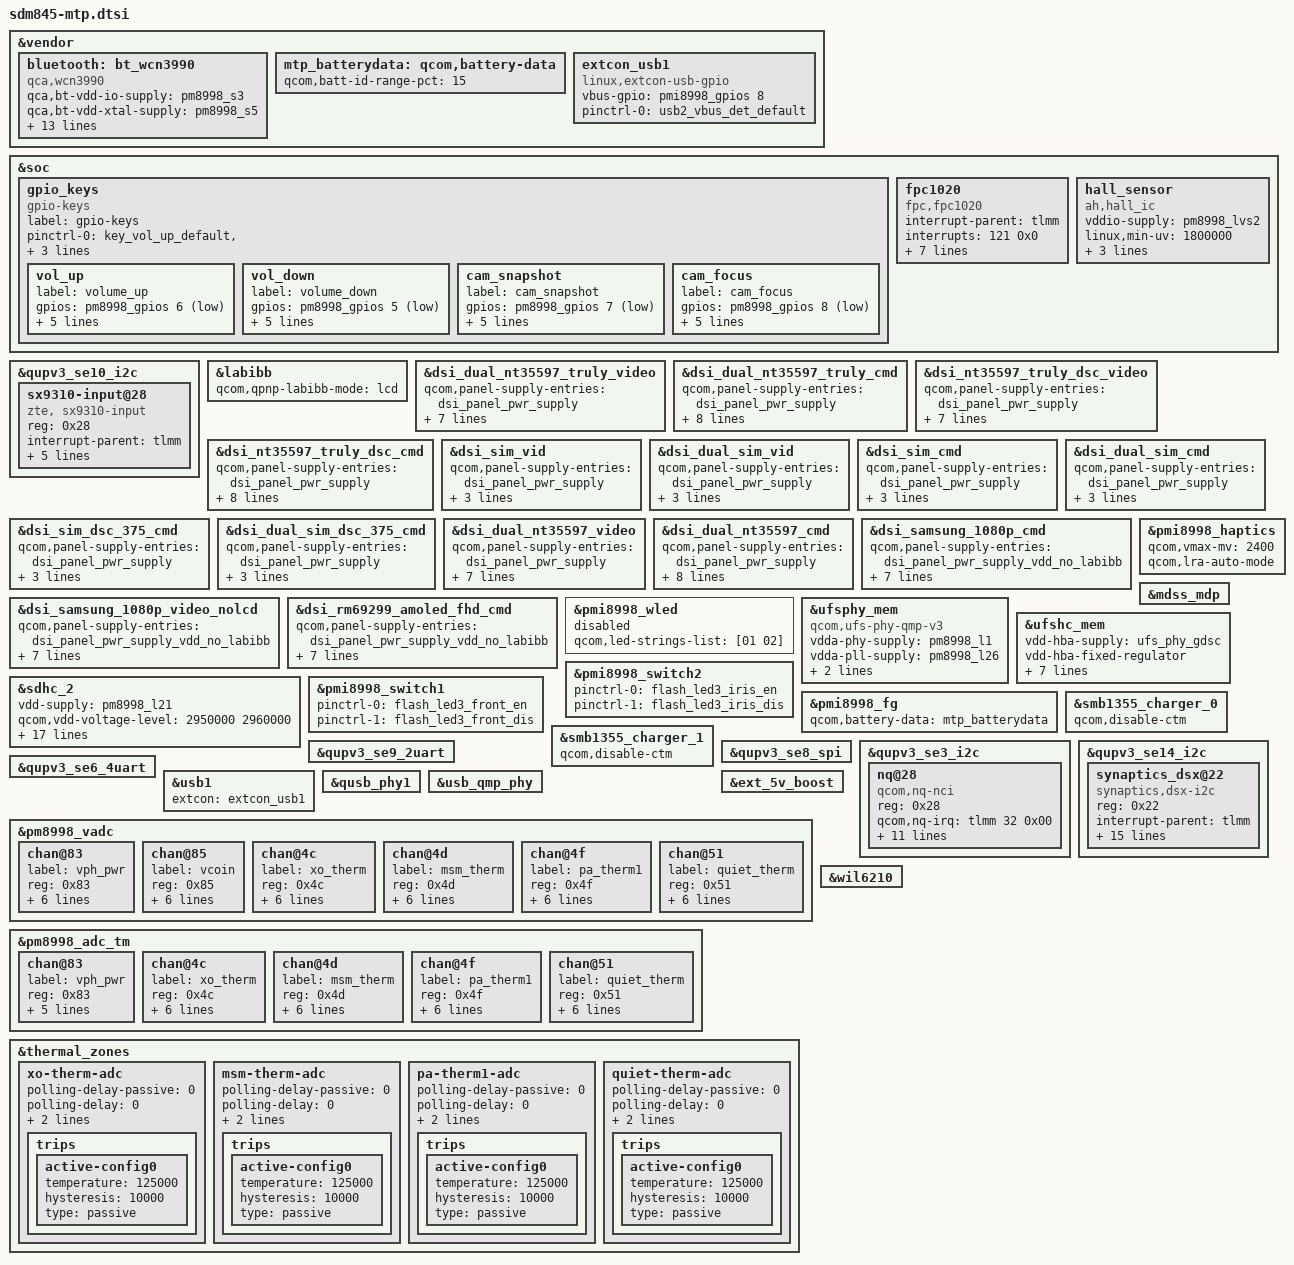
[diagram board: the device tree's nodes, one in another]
/* Copyright (c) 2016-2018, The Linux Foundation. All rights reserved.
 *
 * This program is free software; you can redistribute it and/or modify
 * it under the terms of the GNU General Public License version 2 and
 * only version 2 as published by the Free Software Foundation.
 *
 * This program is distributed in the hope that it will be useful,
 * but WITHOUT ANY WARRANTY; without even the implied warranty of
 * MERCHANTABILITY or FITNESS FOR A PARTICULAR PURPOSE.  See the
 * GNU General Public License for more details.
 */

#include <dt-bindings/gpio/gpio.h>
#include "sdm845-pmic-overlay.dtsi"
#include "sdm845-pinctrl-overlay.dtsi"
#include "zte-sdm845-camera-sensor-mtp.dtsi"
#include "smb1355.dtsi"

&vendor {
	bluetooth: bt_wcn3990 {
		compatible = "qca,wcn3990";
		qca,bt-vdd-io-supply = <&pm8998_s3>;
		qca,bt-vdd-xtal-supply = <&pm8998_s5>;
		qca,bt-vdd-core-supply = <&pm8998_l7>;
		qca,bt-vdd-pa-supply = <&pm8998_l17>;
		qca,bt-vdd-ldo-supply = <&pm8998_l25>;

		qca,bt-vdd-io-voltage-level = <1352000 1352000>;
		qca,bt-vdd-xtal-voltage-level = <2040000 2040000>;
		qca,bt-vdd-core-voltage-level = <1800000 1800000>;
		qca,bt-vdd-pa-voltage-level = <1304000 1304000>;
		qca,bt-vdd-ldo-voltage-level = <3312000 3312000>;

		qca,bt-vdd-io-current-level = <1>; /* LPM/PFM */
		qca,bt-vdd-xtal-current-level = <1>; /* LPM/PFM */
		qca,bt-vdd-core-current-level = <1>; /* LPM/PFM */
		qca,bt-vdd-pa-current-level = <1>; /* LPM/PFM */
		qca,bt-vdd-ldo-current-level = <1>; /* LPM/PFM */
	};
};

&soc {
	gpio_keys {
		compatible = "gpio-keys";
		label = "gpio-keys";

		pinctrl-names = "default";
		pinctrl-0 = <&key_vol_up_default
			     &key_vol_down_default
			     &key_cam_snapshot_default
			     &key_cam_focus_default>;

		vol_up {
			label = "volume_up";
			gpios = <&pm8998_gpios 6 GPIO_ACTIVE_LOW>;
			linux,input-type = <1>;
			linux,code = <115>;
			gpio-key,wakeup;
			debounce-interval = <15>;
			linux,can-disable;
		};

		/*add by yanshentao start*/
		vol_down {
			label = "volume_down";
			gpios = <&pm8998_gpios 5 GPIO_ACTIVE_LOW>;
			linux,input-type = <1>;
			linux,code = <114>;
			gpio-key,wakeup;
			debounce-interval = <15>;
			linux,can-disable;
		};
		/*add by yanshentao end*/

		cam_snapshot {
			label = "cam_snapshot";
			gpios = <&pm8998_gpios 7 GPIO_ACTIVE_LOW>;
			linux,input-type = <1>;
			linux,code = <766>;
			gpio-key,wakeup;
			debounce-interval = <15>;
			linux,can-disable;
		};

		cam_focus {
			label = "cam_focus";
			gpios = <&pm8998_gpios 8 GPIO_ACTIVE_LOW>;
			linux,input-type = <1>;
			linux,code = <528>;
			gpio-key,wakeup;
			debounce-interval = <15>;
			linux,can-disable;
		};
	};
	fpc1020 {
		status = "ok";
		compatible = "fpc,fpc1020";
		interrupt-parent = <&tlmm>;
		interrupts = <121 0x0>;
		fpc,gpio_rst	= <&tlmm 102 0x0>;
		fpc,gpio_irq	= <&tlmm 121 0x0>;
		fpc,gpio_pwr	= <&tlmm 87 0x0>;
		fpc,enable-on-boot;
		/* fpc,enable-wakeup; */

		pinctrl-names = "fpc1020_reset_reset",
		"fpc1020_reset_active",
		"fpc1020_irq_active";

		pinctrl-0 = <&msm_gpio_102>;
		pinctrl-1 = <&msm_gpio_102_output_high>;
		pinctrl-2 = <&msm_gpio_121>;
	};
	hall_sensor {
		compatible = "ah,hall_ic";
		vddio-supply = <&pm8998_lvs2>;
		linux,min-uv = <1800000>;
		linux,max-uv = <1800000>;
		ah,gpio_irq = <&tlmm 124 0x00>;
		linux,name = "hall_sensor";
	};
};

&qupv3_se10_i2c {
	status = "ok";
		sx9310-input@28 {
			compatible = "zte, sx9310-input";
			reg = <0x28>;
			//cc,irq_gpio = <&tlmm 17 0x0>;
			interrupt-parent = <&tlmm>;
			interrupts = <123 2>;
			interrupt-names = "sx9310_irq";
			pinctrl-names = "sx9310_active", "sx9310_sleep";
			pinctrl-0 = <&sx9500_int_active>;
			pinctrl-1 = <&sx9500_int_suspend >;
			vdd-supply = <&pm8998_l19>;
			svdd-supply = <&pm8998_s4>;
		};
};


&labibb {
	status = "ok";
	qcom,qpnp-labibb-mode = "lcd";
};

&dsi_dual_nt35597_truly_video {
	qcom,panel-supply-entries = <&dsi_panel_pwr_supply>;
	qcom,mdss-dsi-bl-pmic-control-type = "bl_ctrl_wled";
	qcom,mdss-dsi-bl-min-level = <1>;
	qcom,mdss-dsi-bl-max-level = <4095>;
	qcom,mdss-dsi-mode-sel-gpio-state = "dual_port";
	qcom,panel-mode-gpio = <&tlmm 52 0>;
	qcom,platform-reset-gpio = <&tlmm 6 0>;
};

&dsi_dual_nt35597_truly_cmd {
	qcom,panel-supply-entries = <&dsi_panel_pwr_supply>;
	qcom,mdss-dsi-bl-pmic-control-type = "bl_ctrl_wled";
	qcom,mdss-dsi-bl-min-level = <1>;
	qcom,mdss-dsi-bl-max-level = <4095>;
	qcom,mdss-dsi-mode-sel-gpio-state = "dual_port";
	qcom,panel-mode-gpio = <&tlmm 52 0>;
	qcom,platform-reset-gpio = <&tlmm 6 0>;
	qcom,platform-te-gpio = <&tlmm 10 0>;
};

&dsi_nt35597_truly_dsc_video {
	qcom,panel-supply-entries = <&dsi_panel_pwr_supply>;
	qcom,mdss-dsi-bl-pmic-control-type = "bl_ctrl_wled";
	qcom,mdss-dsi-bl-min-level = <1>;
	qcom,mdss-dsi-bl-max-level = <4095>;
	qcom,mdss-dsi-mode-sel-gpio-state = "single_port";
	qcom,panel-mode-gpio = <&tlmm 52 0>;
	qcom,platform-reset-gpio = <&tlmm 6 0>;
};

&dsi_nt35597_truly_dsc_cmd {
	qcom,panel-supply-entries = <&dsi_panel_pwr_supply>;
	qcom,mdss-dsi-bl-pmic-control-type = "bl_ctrl_wled";
	qcom,mdss-dsi-bl-min-level = <1>;
	qcom,mdss-dsi-bl-max-level = <4095>;
	qcom,mdss-dsi-mode-sel-gpio-state = "single_port";
	qcom,panel-mode-gpio = <&tlmm 52 0>;
	qcom,platform-reset-gpio = <&tlmm 6 0>;
	qcom,platform-te-gpio = <&tlmm 10 0>;
};

&dsi_sim_vid {
	qcom,panel-supply-entries = <&dsi_panel_pwr_supply>;
	qcom,mdss-dsi-bl-pmic-control-type = "bl_ctrl_wled";
	qcom,platform-reset-gpio = <&tlmm 6 0>;
};

&dsi_dual_sim_vid {
	qcom,panel-supply-entries = <&dsi_panel_pwr_supply>;
	qcom,mdss-dsi-bl-pmic-control-type = "bl_ctrl_wled";
	qcom,platform-reset-gpio = <&tlmm 6 0>;
};

&dsi_sim_cmd {
	qcom,panel-supply-entries = <&dsi_panel_pwr_supply>;
	qcom,mdss-dsi-bl-pmic-control-type = "bl_ctrl_wled";
	qcom,platform-reset-gpio = <&tlmm 6 0>;
};

&dsi_dual_sim_cmd {
	qcom,panel-supply-entries = <&dsi_panel_pwr_supply>;
	qcom,mdss-dsi-bl-pmic-control-type = "bl_ctrl_wled";
	qcom,platform-reset-gpio = <&tlmm 6 0>;
};

&dsi_sim_dsc_375_cmd {
	qcom,panel-supply-entries = <&dsi_panel_pwr_supply>;
	qcom,mdss-dsi-bl-pmic-control-type = "bl_ctrl_wled";
	qcom,platform-reset-gpio = <&tlmm 6 0>;
};

&dsi_dual_sim_dsc_375_cmd {
	qcom,panel-supply-entries = <&dsi_panel_pwr_supply>;
	qcom,mdss-dsi-bl-pmic-control-type = "bl_ctrl_wled";
	qcom,platform-reset-gpio = <&tlmm 6 0>;
};

&dsi_dual_nt35597_video {
	qcom,panel-supply-entries = <&dsi_panel_pwr_supply>;
	qcom,mdss-dsi-bl-pmic-control-type = "bl_ctrl_wled";
	qcom,mdss-dsi-bl-min-level = <1>;
	qcom,mdss-dsi-bl-max-level = <4095>;
	qcom,mdss-dsi-mode-sel-gpio-state = "dual_port";
	qcom,panel-mode-gpio = <&tlmm 52 0>;
	qcom,platform-reset-gpio = <&tlmm 6 0>;
};

&dsi_dual_nt35597_cmd {
	qcom,panel-supply-entries = <&dsi_panel_pwr_supply>;
	qcom,mdss-dsi-bl-pmic-control-type = "bl_ctrl_wled";
	qcom,mdss-dsi-bl-min-level = <1>;
	qcom,mdss-dsi-bl-max-level = <4095>;
	qcom,mdss-dsi-mode-sel-gpio-state = "dual_port";
	qcom,panel-mode-gpio = <&tlmm 52 0>;
	qcom,platform-reset-gpio = <&tlmm 6 0>;
	qcom,platform-te-gpio = <&tlmm 10 0>;
};

&dsi_samsung_1080p_cmd {
	qcom,panel-supply-entries = <&dsi_panel_pwr_supply_vdd_no_labibb>;
	qcom,mdss-dsi-mode-sel-gpio-state = "single_port";
	qcom,5v-boost-gpio = <&tlmm 40 0>;
	qcom,platform-reset-gpio = <&tlmm 6 0>;
	qcom,platform-te-gpio = <&tlmm 10 0>;
	qcom,dsp-reset-gpio = <&tlmm 23 0>;
	qcom,dsp-dsp_1v1 = <&tlmm 26 0>;
	qcom,dsp-wakeup-gpio = <&tlmm 24 0>;
};

&dsi_samsung_1080p_video_nolcd {
	qcom,panel-supply-entries = <&dsi_panel_pwr_supply_vdd_no_labibb>;
	qcom,mdss-dsi-mode-sel-gpio-state = "single_port";
	qcom,5v-boost-gpio = <&tlmm 40 0>;
	qcom,platform-reset-gpio = <&tlmm 6 0>;
	qcom,platform-te-gpio = <&tlmm 10 0>;
	qcom,dsp-reset-gpio = <&tlmm 23 0>;
	qcom,dsp-dsp_1v1 = <&tlmm 26 0>;
	qcom,dsp-wakeup-gpio = <&tlmm 24 0>;
};

&dsi_rm69299_amoled_fhd_cmd {
	qcom,panel-supply-entries = <&dsi_panel_pwr_supply_vdd_no_labibb>;
	qcom,mdss-dsi-mode-sel-gpio-state = "single_port";
	qcom,5v-boost-gpio = <&tlmm 40 0>;
	qcom,platform-reset-gpio = <&tlmm 6 0>;
	qcom,platform-te-gpio = <&tlmm 10 0>;
	qcom,dsp-reset-gpio = <&tlmm 23 0>;
	qcom,dsp-dsp_1v1 = <&tlmm 26 0>;
	qcom,dsp-wakeup-gpio = <&tlmm 24 0>;
};

&pmi8998_wled {
	status = "disabled";
	qcom,led-strings-list = [01 02];
};

&pmi8998_haptics {
	qcom,vmax-mv = <2400>;
	qcom,lra-auto-mode;
	status = "okay";
};

&mdss_mdp {
	#cooling-cells = <2>;
};

&ufsphy_mem {
	compatible = "qcom,ufs-phy-qmp-v3";

	vdda-phy-supply = <&pm8998_l1>; /* 0.88v */
	vdda-pll-supply = <&pm8998_l26>; /* 1.2v */
	vdda-phy-max-microamp = <62900>;
	vdda-pll-max-microamp = <18300>;

	status = "ok";
};

&ufshc_mem {
	vdd-hba-supply = <&ufs_phy_gdsc>;
	vdd-hba-fixed-regulator;
	vcc-supply = <&pm8998_l20>;
	vcc-voltage-level = <2950000 2960000>;
	vccq2-supply = <&pm8998_s4>;
	vcc-max-microamp = <600000>;
	vccq2-max-microamp = <600000>;

	qcom,vddp-ref-clk-supply = <&pm8998_l2>;
	qcom,vddp-ref-clk-max-microamp = <100>;

	status = "ok";
};

&sdhc_2 {
	vdd-supply = <&pm8998_l21>;
	qcom,vdd-voltage-level = <2950000 2960000>;
	qcom,vdd-current-level = <200 800000>;

	vdd-io-supply = <&pm8998_l13>;
	qcom,vdd-io-voltage-level = <1808000 2960000>;
	qcom,vdd-io-current-level = <200 22000>;

	pinctrl-names = "active", "sleep", "ds_400KHz",
			"ds_50MHz", "ds_100MHz", "ds_200MHz";
	pinctrl-0 = <&sdc2_clk_on  &sdc2_cmd_on &sdc2_data_on &storage_cd>;
	pinctrl-1 = <&sdc2_clk_off &sdc2_cmd_off &sdc2_data_off &storage_cd>;
	pinctrl-2 = <&sdc2_clk_ds_400KHz
			&sdc2_cmd_ds_400KHz &sdc2_data_ds_400KHz>;
	pinctrl-3 = <&sdc2_clk_ds_50MHz
			&sdc2_cmd_ds_50MHz &sdc2_data_ds_50MHz>;
	pinctrl-4 = <&sdc2_clk_ds_100MHz
			&sdc2_cmd_ds_100MHz &sdc2_data_ds_100MHz>;
	pinctrl-5 = <&sdc2_clk_ds_200MHz
			&sdc2_cmd_ds_200MHz &sdc2_data_ds_200MHz>;

	cd-gpios = <&tlmm 126 GPIO_ACTIVE_LOW>;

	status = "ok";
};

&pmi8998_switch1 {
	pinctrl-names = "led_enable", "led_disable";
	pinctrl-0 = <&flash_led3_front_en>;
	pinctrl-1 = <&flash_led3_front_dis>;
};

&pmi8998_switch2 {
	pinctrl-names = "led_enable", "led_disable";
	pinctrl-0 = <&flash_led3_iris_en>;
	pinctrl-1 = <&flash_led3_iris_dis>;
};

&vendor {
	mtp_batterydata: qcom,battery-data {
		qcom,batt-id-range-pct = <15>;
		#include "fg-gen3-batterydata-itech-3000mah.dtsi"
		#include "fg-gen3-batterydata-ascent-3450mah.dtsi"
		#include "fg-gen3-batterydata-demo-6000mah.dtsi"
	};

	extcon_usb1: extcon_usb1 {
		compatible = "linux,extcon-usb-gpio";
		vbus-gpio = <&pmi8998_gpios 8 GPIO_ACTIVE_HIGH>;

		pinctrl-names = "default";
		pinctrl-0 = <&usb2_vbus_det_default>;
	};
};

&pmi8998_fg {
	qcom,battery-data = <&mtp_batterydata>;
};

&smb1355_charger_0 {
	status = "ok";
	qcom,disable-ctm;
};

&smb1355_charger_1 {
	status = "ok";
	qcom,disable-ctm;
};

&qupv3_se9_2uart {
	status = "ok";
};

&qupv3_se8_spi {
	status = "ok";
};

&qupv3_se3_i2c {
	status = "ok";
	nq@28 {
		compatible = "qcom,nq-nci";
		reg = <0x28>;
		qcom,nq-irq = <&tlmm 32 0x00>;
		qcom,nq-ven = <&tlmm 12 0x00>;
		qcom,nq-firm = <&tlmm 31 0x00>;
		qcom,nq-clkreq = <&pm8998_gpios 21 0x00>;
		qcom,nq-esepwr = <&tlmm 116 0x00>;
		interrupt-parent = <&tlmm>;
		qcom,clk-src = "BBCLK3";
		interrupts = <32 0>;
		interrupt-names = "nfc_irq";
		pinctrl-names = "nfc_active", "nfc_suspend";
		pinctrl-0 = <&nfc_int_active
			     &nfc_enable_active
			     &nfc_clk_default>;
		pinctrl-1 = <&nfc_int_suspend &nfc_enable_suspend>;
                clocks = <&clock_rpmh RPMH_LN_BB_CLK3>;
                clock-names = "ref_clk";

	};
};

&qupv3_se10_i2c {
	status = "ok";
};

&qupv3_se14_i2c {
	status = "ok";
	synaptics_dsx@22 {
		compatible = "synaptics,dsx-i2c";
		reg = <0x22>;
		interrupt-parent = <&tlmm>;
		interrupts = <125 0x2008>;
		vdd-supply = <&pm8998_l28>;
		avdd-supply = <&pm8998_l14>;
		synaptics,pwr-reg-name = "vdd";
		synaptics,bus-reg-name = "avdd";
		pinctrl-names = "pmx_ts_active", "pmx_ts_suspend";
		pinctrl-0 = <&ts_active>;
		pinctrl-1 = <&ts_suspend>;
		synaptics,ub-i2c-addr = <0x2c>;
		synaptics,reset-gpio = <&tlmm 99 0>;
		synaptics,irq-gpio = <&tlmm 125 0x2008>;
		synaptics,irq-on-state = <0>;
		synaptics,power-delay-ms = <100>;
		synaptics,reset-delay-ms = <100>;
		synaptics,reset-on-state = <0>;
		synaptics,reset-active-ms = <20>;
	};
};

&qupv3_se6_4uart {
	status = "ok";
};

&usb1 {
	status = "okay";
	extcon = <&extcon_usb1>;
};

&qusb_phy1 {
	status = "okay";
};

&ext_5v_boost {
	status = "ok";
};

&usb_qmp_phy {
	status = "okay";
};

&pm8998_vadc {
	chan@83 {
		label = "vph_pwr";
		reg = <0x83>;
		qcom,decimation = <2>;
		qcom,pre-div-channel-scaling = <1>;
		qcom,calibration-type = "absolute";
		qcom,scale-function = <0>;
		qcom,hw-settle-time = <0>;
		qcom,fast-avg-setup = <0>;
	};

	chan@85 {
		label = "vcoin";
		reg = <0x85>;
		qcom,decimation = <2>;
		qcom,pre-div-channel-scaling = <1>;
		qcom,calibration-type = "absolute";
		qcom,scale-function = <0>;
		qcom,hw-settle-time = <0>;
		qcom,fast-avg-setup = <0>;
	};

	chan@4c {
		label = "xo_therm";
		reg = <0x4c>;
		qcom,decimation = <2>;
		qcom,pre-div-channel-scaling = <0>;
		qcom,calibration-type = "ratiometric";
		qcom,scale-function = <4>;
		qcom,hw-settle-time = <2>;
		qcom,fast-avg-setup = <0>;
	};

	chan@4d {
		label = "msm_therm";
		reg = <0x4d>;
		qcom,decimation = <2>;
		qcom,pre-div-channel-scaling = <0>;
		qcom,calibration-type = "ratiometric";
		qcom,scale-function = <2>;
		qcom,hw-settle-time = <2>;
		qcom,fast-avg-setup = <0>;
	};

	chan@4f {
		label = "pa_therm1";
		reg = <0x4f>;
		qcom,decimation = <2>;
		qcom,pre-div-channel-scaling = <0>;
		qcom,calibration-type = "ratiometric";
		qcom,scale-function = <2>;
		qcom,hw-settle-time = <2>;
		qcom,fast-avg-setup = <0>;
	};

	chan@51 {
		label = "quiet_therm";
		reg = <0x51>;
		qcom,decimation = <2>;
		qcom,pre-div-channel-scaling = <0>;
		qcom,calibration-type = "ratiometric";
		qcom,scale-function = <2>;
		qcom,hw-settle-time = <2>;
		qcom,fast-avg-setup = <0>;
	};
};

&pm8998_adc_tm {
	chan@83 {
		label = "vph_pwr";
		reg = <0x83>;
		qcom,pre-div-channel-scaling = <1>;
		qcom,calibration-type = "absolute";
		qcom,scale-function = <0>;
		qcom,hw-settle-time = <0>;
		qcom,btm-channel-number = <0x60>;
	};

	chan@4c {
		label = "xo_therm";
		reg = <0x4c>;
		qcom,pre-div-channel-scaling = <0>;
		qcom,calibration-type = "ratiometric";
		qcom,scale-function = <4>;
		qcom,hw-settle-time = <2>;
		qcom,btm-channel-number = <0x68>;
		qcom,thermal-node;
	};

	chan@4d {
		label = "msm_therm";
		reg = <0x4d>;
		qcom,pre-div-channel-scaling = <0>;
		qcom,calibration-type = "ratiometric";
		qcom,scale-function = <2>;
		qcom,hw-settle-time = <2>;
		qcom,btm-channel-number = <0x70>;
		qcom,thermal-node;
	};

	chan@4f {
		label = "pa_therm1";
		reg = <0x4f>;
		qcom,pre-div-channel-scaling = <0>;
		qcom,calibration-type = "ratiometric";
		qcom,scale-function = <2>;
		qcom,hw-settle-time = <2>;
		qcom,btm-channel-number = <0x78>;
		qcom,thermal-node;
	};

	chan@51 {
		label = "quiet_therm";
		reg = <0x51>;
		qcom,pre-div-channel-scaling = <0>;
		qcom,calibration-type = "ratiometric";
		qcom,scale-function = <2>;
		qcom,hw-settle-time = <2>;
		qcom,btm-channel-number = <0x80>;
		qcom,thermal-node;
	};
};

&thermal_zones {
	xo-therm-adc {
		polling-delay-passive = <0>;
		polling-delay = <0>;
		thermal-sensors = <&pm8998_adc_tm 0x4c>;
		thermal-governor = "user_space";

		trips {
			active-config0 {
				temperature = <125000>;
				hysteresis = <10000>;
				type = "passive";
			};
		};
	};

	msm-therm-adc {
		polling-delay-passive = <0>;
		polling-delay = <0>;
		thermal-sensors = <&pm8998_adc_tm 0x4d>;
		thermal-governor = "user_space";

		trips {
			active-config0 {
				temperature = <125000>;
				hysteresis = <10000>;
				type = "passive";
			};
		};
	};

	pa-therm1-adc {
		polling-delay-passive = <0>;
		polling-delay = <0>;
		thermal-sensors = <&pm8998_adc_tm 0x4f>;
		thermal-governor = "user_space";

		trips {
			active-config0 {
				temperature = <125000>;
				hysteresis = <10000>;
				type = "passive";
			};
		};
	};

	quiet-therm-adc {
		polling-delay-passive = <0>;
		polling-delay = <0>;
		thermal-sensors = <&pm8998_adc_tm 0x51>;
		thermal-governor = "user_space";

		trips {
			active-config0 {
				temperature = <125000>;
				hysteresis = <10000>;
				type = "passive";
			};
		};
	};
};

&wil6210 {
	status = "ok";
};
